# ESP32-C2 register map
Vendor: ESPRESSIF SYSTEMS (SHANGHAI) CO., LTD.; Series: ESP32 C-Series; File version: 11
CPU: RV32IMC r0p0, little endian, no MPU, no FPU, 0 interrupt priority bits
Address unit: 32 bits
Registers are 32-bit, read-write, reset 0x0 unless marked. A register's access mark holds for its fields unless they carry their own. Offsets are from the block's base; [hi:lo] are bit positions; lines under a group give offsets from that group; {n}, {i} and the like mark numbered series.

## SYSTIMER — System Timer
Base 0x60023000
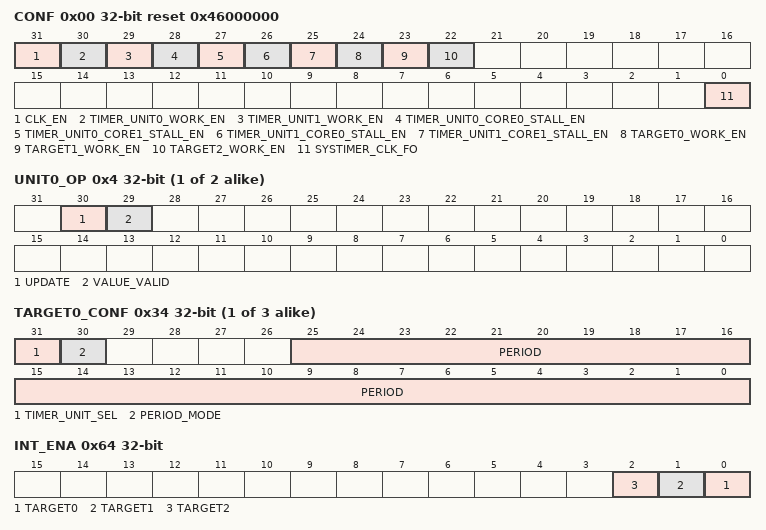
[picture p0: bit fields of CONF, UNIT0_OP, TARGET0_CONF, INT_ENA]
0x00 CONF reset 0x46000000 — Configure system timer clock
  [31] CLK_EN — register file clk gating
  [30] TIMER_UNIT0_WORK_EN — timer unit0 work enable
  [29] TIMER_UNIT1_WORK_EN — timer unit1 work enable
  [28] TIMER_UNIT0_CORE0_STALL_EN — If timer unit0 is stalled when core0 stalled
  [27] TIMER_UNIT0_CORE1_STALL_EN — If timer unit0 is stalled when core1 stalled
  [26] TIMER_UNIT1_CORE0_STALL_EN — If timer unit1 is stalled when core0 stalled
  [25] TIMER_UNIT1_CORE1_STALL_EN — If timer unit1 is stalled when core1 stalled
  [24] TARGET0_WORK_EN — target0 work enable
  [23] TARGET1_WORK_EN — target1 work enable
  [22] TARGET2_WORK_EN — target2 work enable
  [0] SYSTIMER_CLK_FO — systimer clock force on
{0x4+4i} UNIT{i}_OP (i=0..1) access per field — system timer unit{i} value update register
  [30] UPDATE wo — update timer_unit0
  [29] VALUE_VALID ro — timer value is sync and valid
{0xC+8i} UNIT{i}LOAD (i=0..1) group — Cluster UNIT{i}LOAD, containing UNIT?_LOAD_HI, UNIT?_LOAD_LO
  0x00 HI — system timer unit0 value high load register
    [19:0] LOAD_HI — timer unit0 load high 20 bits
  0x04 LO — system timer unit0 value low load register
    [31:0] LOAD_LO — timer unit0 load low 32 bits
{0x1C+8i} TRGT{i} (i=0..2) group — Cluster TRGT{i}, containing TARGET?_HI, TARGET?_LO
  0x00 HI — system timer comp0 value high register
    [19:0] HI — timer taget0 high 20 bits
  0x04 LO — system timer comp0 value low register
    [31:0] LO — timer taget0 low 32 bits
{0x34+4i} TARGET{i}_CONF (i=0..2) — system timer comp{i} target mode register
  [31] TIMER_UNIT_SEL — select which unit to compare
  [30] PERIOD_MODE — Set target0 to period mode
  [25:0] PERIOD — target0 period
{0x40+8i} UNIT{i}_VALUE (i=0..1) group — Cluster UNIT{i}_VALUE, containing UNIT?_VALUE_HI, UNIT?_VALUE_LO
  0x00 HI ro — system timer unit0 value high register
    [19:0] VALUE_HI — timer read value high 20bits
  0x04 LO ro — system timer unit0 value low register
    [31:0] VALUE_LO — timer read value low 32bits
{0x50+4i} COMP{i}_LOAD (i=0..2) wo — system timer comp{i} conf sync register
  [0] LOAD — timer comp0 sync enable signal
{0x5C+4i} UNIT{i}_LOAD (i=0..1) wo — system timer unit{i} conf sync register
  [0] LOAD — timer unit0 sync enable signal
0x64 INT_ENA — systimer interrupt enable register
  [n] TARGET{n} (n=0..2) — interupt{n} enable
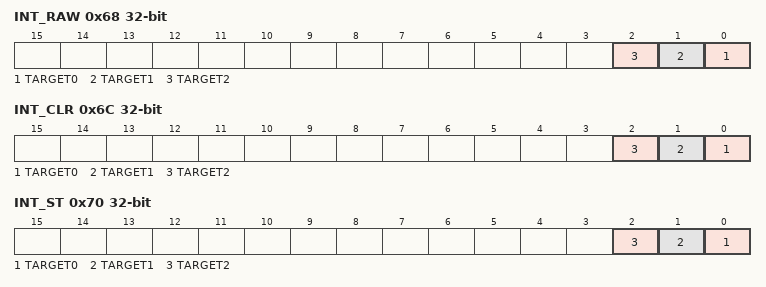
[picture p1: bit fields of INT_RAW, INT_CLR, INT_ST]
0x68 INT_RAW — systimer interrupt raw register
  [n] TARGET{n} (n=0..2) — interupt{n} raw
0x6C INT_CLR wo — systimer interrupt clear register
  [n] TARGET{n} (n=0..2) write-1-clears — interupt{n} clear
0x70 INT_ST ro — systimer interrupt status register
  [n] TARGET{n} (n=0..2) — interupt{n} status
0xFC DATE — system timer version control register

## XTS_AES — XTS-AES-128 Flash Encryption
Base 0x600CC000
{0x0+4i} PLAIN_MEM[{i}] (i=0..3) access not given — The memory that stores plaintext
0x40 LINESIZE — XTS-AES line-size register
  [0] LINESIZE — This bit stores the line size parameter. 0: 16Byte, 1: 32Byte.
0x44 DESTINATION — XTS-AES destination register
  [0] DESTINATION — This bit stores the destination. 0: flash(default). 1: reserved.
0x48 PHYSICAL_ADDRESS — XTS-AES physical address register
  [29:0] PHYSICAL_ADDRESS — Those bits stores the physical address. If linesize is 16-byte, the physical address should be aligned of 16 bytes. If linesize is 32-byte, the physical address should be aligned of 32 bytes.
0x4C TRIGGER wo — XTS-AES trigger register
  [0] TRIGGER — Set this bit to start manual encryption calculation
0x50 RELEASE wo — XTS-AES release register
  [0] RELEASE — Set this bit to release the manual encrypted result, after that the result will be visible to spi
0x54 DESTROY wo — XTS-AES destroy register
  [0] DESTROY — Set this bit to destroy XTS-AES result.
0x58 STATE ro — XTS-AES status register
  [1:0] STATE — Those bits shows XTS-AES status. 0=IDLE, 1=WORK, 2=RELEASE, 3=USE. IDLE means that XTS-AES is idle. WORK means that XTS-AES is busy with calculation. RELEASE means the encrypted result is generated but not visible to mspi. USE means that the encrypted result is visible to mspi.
0x5C DATE — XTS-AES version control register
